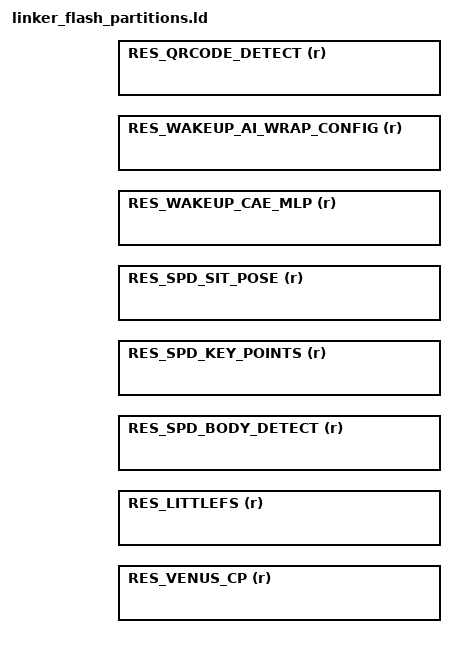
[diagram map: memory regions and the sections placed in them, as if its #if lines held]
/*
 * Copyright (c) 2013-2014 Wind River Systems, Inc.
 *
 * SPDX-License-Identifier: Apache-2.0
 */

/**
 * @file
 * @brief Linker command/script file
 *
 * Linker script for the Cortex-M platforms.
 */

#include <zephyr/linker/sections.h>
#include <zephyr/devicetree.h>

#include <zephyr/linker/linker-defs.h>
#include <zephyr/linker/linker-tool.h>

/** enable CONFIG_SRAM2 or any other partition in soc Kconfig,
 * this is just an example to show relocation of code/data/bss script
 */

MEMORY
{
    RES_VENUS_CP            (r) : ORIGIN = (CONFIG_FLASH_BASE_ADDRESS + CONFIG_FLASH_RES_IMAGE_ADDRESS), LENGTH = CONFIG_FLASH_RES_IMAGE_SIZE

    RES_LITTLEFS            (r) : ORIGIN = (CONFIG_FLASH_BASE_ADDRESS + CONFIG_FLASH_RES_LITTLEFS_IMAGE_ADDRESS), LENGTH = CONFIG_FLASH_RES_LITTLEFS_IMAGE_SIZE

#if defined(CONFIG_CAPABILITY_SPD)
    RES_SPD_BODY_DETECT     (r) : ORIGIN = (CONFIG_FLASH_BASE_ADDRESS + CONFIG_FLASH_RES_SPD_BODY_DETECT_ADDRESS), LENGTH = CONFIG_FLASH_RES_SPD_BODY_DETECT_SIZE
    RES_SPD_KEY_POINTS      (r) : ORIGIN = (CONFIG_FLASH_BASE_ADDRESS + CONFIG_FLASH_RES_SPD_KEY_POINTS_ADDRESS), LENGTH = CONFIG_FLASH_RES_SPD_KEY_POINTS_SIZE
    RES_SPD_SIT_POSE        (r) : ORIGIN = (CONFIG_FLASH_BASE_ADDRESS + CONFIG_FLASH_RES_SPD_SIT_POSE_ADDRESS), LENGTH = CONFIG_FLASH_RES_SPD_SIT_POSE_SIZE
#endif

#if defined(CONFIG_CAPABILITY_WAKEUP)
    RES_WAKEUP_CAE_MLP      (r) : ORIGIN = (CONFIG_FLASH_BASE_ADDRESS + CONFIG_FLASH_RES_WAKEUP_CAE_MLP_ADDRESS), LENGTH = CONFIG_FLASH_RES_WAKEUP_CAE_MLP_SIZE
    RES_WAKEUP_AI_WRAP_CONFIG (r) : ORIGIN = (CONFIG_FLASH_BASE_ADDRESS + CONFIG_FLASH_RES_WAKEUP_AI_WRAP_CONF_ADDRESS), LENGTH = CONFIG_FLASH_RES_WAKEUP_AI_WRAP_CONF_SIZE
#endif

#if defined(CONFIG_CAPABILITY_QRCODE)
    RES_QRCODE_DETECT     (r) : ORIGIN = (CONFIG_FLASH_BASE_ADDRESS + CONFIG_FLASH_RES_QRCODE_DETECT_ADDRESS), LENGTH = CONFIG_FLASH_RES_QRCODE_DETECT_SIZE
#endif

}

#include <linker.ld>
